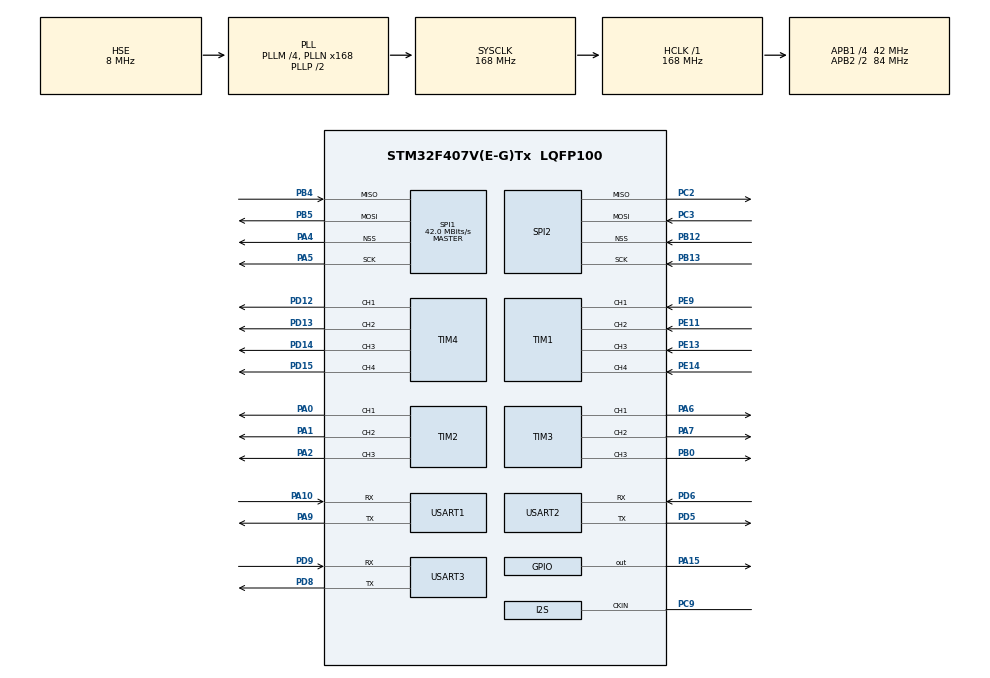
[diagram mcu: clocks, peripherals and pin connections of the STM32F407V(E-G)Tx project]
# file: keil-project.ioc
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Mcu.Family=STM32F4
Mcu.Name=STM32F407V(E-G)Tx
Mcu.Package=LQFP100
NVIC.PriorityGroup=NVIC_PRIORITYGROUP_4
PA0-WKUP.Signal=S_TIM2_CH1_ETR
PA1.Signal=S_TIM2_CH2
PA10.Mode=Asynchronous
PA10.Signal=USART1_RX
PA11.Signal=USART1_CTS
PA12.Signal=USART1_RTS
PA13.Mode=Trace-Asynchronous_SW
PA13.Signal=SYS_JTMS-SWDIO
PA14.Mode=Trace-Asynchronous_SW
PA14.Signal=SYS_JTCK-SWCLK
PA15.Signal=GPIO_Output
PA2.Signal=S_TIM2_CH3
PA4.Mode=NSS_Signal_Hard_Output
PA4.Signal=SPI1_NSS
PA5.Mode=Full_Duplex_Master
PA5.Signal=SPI1_SCK
PA6.Signal=S_TIM3_CH1
PA7.Signal=S_TIM3_CH2
PA8.Signal=USART1_CK
PA9.Mode=Asynchronous
PA9.Signal=USART1_TX
PB0.Signal=S_TIM3_CH3
PB12.Mode=NSS_Signal_Hard_Input
PB12.Signal=SPI2_NSS
PB13.Mode=Full_Duplex_Slave
PB13.Signal=SPI2_SCK
PB3.Mode=Trace-Asynchronous_SW
PB3.Signal=SYS_JTDO-SWO
PB4.Mode=Full_Duplex_Master
PB4.Signal=SPI1_MISO
PB5.Mode=Full_Duplex_Master
PB5.Signal=SPI1_MOSI
PC10.Signal=I2S3_CK
PC11.Signal=I2S3_ext_SD
PC12.Signal=I2S3_SD
PC2.Mode=Full_Duplex_Slave
PC2.Signal=SPI2_MISO
PC3.Mode=Full_Duplex_Slave
PC3.Signal=SPI2_MOSI
PC9.Mode=Audio_ClockIn
PC9.Signal=I2S_CKIN
PD12.Signal=S_TIM4_CH1
PD13.Signal=S_TIM4_CH2
PD14.Signal=S_TIM4_CH3
PD15.Signal=S_TIM4_CH4
PD5.Mode=Asynchronous
PD5.Signal=USART2_TX
PD6.Mode=Asynchronous
PD6.Signal=USART2_RX
PD8.Mode=Asynchronous
PD8.Signal=USART3_TX
PD9.Mode=Asynchronous
PD9.Signal=USART3_RX
PE11.Signal=S_TIM1_CH2
PE13.Signal=S_TIM1_CH3
PE14.Signal=S_TIM1_CH4
PE9.Signal=S_TIM1_CH1
PH0-OSC_IN.Mode=HSE-External-Clock-Source
PH0-OSC_IN.Signal=RCC_OSC_IN
PH1-OSC_OUT.Mode=HSE-External-Clock-Source
PH1-OSC_OUT.Signal=RCC_OSC_OUT
ProjectManager.HeapSize=0x200
ProjectManager.StackSize=0x400
ProjectManager.TargetToolchain=MDK-ARM V4
RCC.48MHZClocksFreq_Value=48000000
RCC.AHBFreq_Value=168000000
RCC.APB1CLKDivider=RCC_HCLK_DIV4
RCC.APB1Freq_Value=42000000
RCC.APB1TimFreq_Value=84000000
RCC.APB2CLKDivider=RCC_HCLK_DIV2
RCC.APB2Freq_Value=84000000
RCC.APB2TimFreq_Value=168000000
RCC.CortexFreq_Value=168000000
RCC.HCLKFreq_Value=168000000
RCC.HSE_VALUE=8000000
RCC.HSI_VALUE=16000000
RCC.I2SClockSource=I2S_CLOCK_EXTERNAL
RCC.LSE_VALUE=32768
RCC.PLLM=4
RCC.PLLN=168
RCC.PLLQ=7
RCC.PLLSourceVirtual=RCC_PLLSOURCE_HSE
RCC.SYSCLKFreq_VALUE=168000000
RCC.SYSCLKSource=RCC_SYSCLKSOURCE_PLLCLK
RCC.VCOOutputFreq_Value=336000000
SH.S_TIM1_CH1.0=TIM1_CH1,Input_Capture1_from_TI1
SH.S_TIM1_CH2.0=TIM1_CH2,Input_Capture2_from_TI2
SH.S_TIM1_CH3.0=TIM1_CH3,Input_Capture3_from_TI3
SH.S_TIM1_CH4.0=TIM1_CH4,Input_Capture4_from_TI4
SH.S_TIM2_CH1_ETR.0=TIM2_CH1,PWM Generation1 CH1
SH.S_TIM2_CH2.0=TIM2_CH2,PWM Generation2 CH2
SH.S_TIM2_CH3.0=TIM2_CH3,PWM Generation3 CH3
SH.S_TIM3_CH1.0=TIM3_CH1,PWM Generation1 CH1
SH.S_TIM3_CH2.0=TIM3_CH2,PWM Generation2 CH2
SH.S_TIM3_CH3.0=TIM3_CH3,PWM Generation3 CH3
SH.S_TIM4_CH1.0=TIM4_CH1,PWM Generation1 CH1
SH.S_TIM4_CH2.0=TIM4_CH2,PWM Generation2 CH2
SH.S_TIM4_CH3.0=TIM4_CH3,PWM Generation3 CH3
SH.S_TIM4_CH4.0=TIM4_CH4,PWM Generation4 CH4
SPI1.CalculateBaudRate=42.0 MBits/s
SPI1.Mode=SPI_MODE_MASTER
SPI1.VirtualNSS=VM_NSSHARD
SPI2.VirtualNSS=VM_NSSHARD
SPI2.VirtualType=VM_SLAVE
TIM1.Channel-Input_Capture2_from_TI2=TIM_CHANNEL_2
TIM1.Channel-Input_Capture3_from_TI3=TIM_CHANNEL_3
TIM1.Channel-Input_Capture4_from_TI4=TIM_CHANNEL_4
TIM2.Channel-PWM\ Generation2\ CH2=TIM_CHANNEL_2
TIM2.Channel-PWM\ Generation3\ CH3=TIM_CHANNEL_3
TIM3.Channel-PWM\ Generation2\ CH2=TIM_CHANNEL_2
TIM3.Channel-PWM\ Generation3\ CH3=TIM_CHANNEL_3
TIM4.Channel-PWM\ Generation2\ CH2=TIM_CHANNEL_2
TIM4.Channel-PWM\ Generation3\ CH3=TIM_CHANNEL_3
TIM4.Channel-PWM\ Generation4\ CH4=TIM_CHANNEL_4
VP_TIM1_VS_ClockSourceINT.Mode=Internal
VP_TIM2_VS_ClockSourceINT.Mode=Internal
VP_TIM3_VS_ClockSourceINT.Mode=Internal
VP_TIM4_VS_ClockSourceINT.Mode=Internal
board=keil-project

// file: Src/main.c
/**
  ******************************************************************************
  * File Name          : main.c
  * Description        : Main program body
  ******************************************************************************
  *
  * COPYRIGHT(c) 2016 STMicroelectronics
  *
  * Redistribution and use in source and binary forms, with or without modification,
  * are permitted provided that the following conditions are met:
  *   1. Redistributions of source code must retain the above copyright notice,
  *      this list of conditions and the following disclaimer.
  *   2. Redistributions in binary form must reproduce the above copyright notice,
  *      this list of conditions and the following disclaimer in the documentation
  *      and/or other materials provided with the distribution.
  *   3. Neither the name of STMicroelectronics nor the names of its contributors
  *      may be used to endorse or promote products derived from this software
  *      without specific prior written permission.
  *
  * THIS SOFTWARE IS PROVIDED BY THE COPYRIGHT HOLDERS AND CONTRIBUTORS "AS IS"
  * AND ANY EXPRESS OR IMPLIED WARRANTIES, INCLUDING, BUT NOT LIMITED TO, THE
  * IMPLIED WARRANTIES OF MERCHANTABILITY AND FITNESS FOR A PARTICULAR PURPOSE ARE
  * DISCLAIMED. IN NO EVENT SHALL THE COPYRIGHT HOLDER OR CONTRIBUTORS BE LIABLE
  * FOR ANY DIRECT, INDIRECT, INCIDENTAL, SPECIAL, EXEMPLARY, OR CONSEQUENTIAL
  * DAMAGES (INCLUDING, BUT NOT LIMITED TO, PROCUREMENT OF SUBSTITUTE GOODS OR
  * SERVICES; LOSS OF USE, DATA, OR PROFITS; OR BUSINESS INTERRUPTION) HOWEVER
  * CAUSED AND ON ANY THEORY OF LIABILITY, WHETHER IN CONTRACT, STRICT LIABILITY,
  * OR TORT (INCLUDING NEGLIGENCE OR OTHERWISE) ARISING IN ANY WAY OUT OF THE USE
  * OF THIS SOFTWARE, EVEN IF ADVISED OF THE POSSIBILITY OF SUCH DAMAGE.
  *
  ******************************************************************************
  */
#include "stm32f4xx_hal.h"

SPI_HandleTypeDef hspi1;
SPI_HandleTypeDef hspi2;

TIM_HandleTypeDef htim1;
TIM_HandleTypeDef htim2;
TIM_HandleTypeDef htim3;
TIM_HandleTypeDef htim4;

UART_HandleTypeDef huart1;
UART_HandleTypeDef huart2;
UART_HandleTypeDef huart3;

/* USER CODE BEGIN PV */
/* Private variables ---------------------------------------------------------*/

/* USER CODE END PV */

void SystemClock_Config(void);
static void MX_GPIO_Init(void);
static void MX_SPI1_Init(void);
static void MX_SPI2_Init(void);
static void MX_TIM1_Init(void);
static void MX_TIM2_Init(void);
static void MX_TIM3_Init(void);
static void MX_TIM4_Init(void);
static void MX_USART1_UART_Init(void);
static void MX_USART2_UART_Init(void);
static void MX_USART3_UART_Init(void);

void HAL_TIM_MspPostInit(TIM_HandleTypeDef *htim);

/* USER CODE BEGIN PFP */
/* Private function prototypes -----------------------------------------------*/

/* USER CODE END PFP */

int main(void)
{

  /* MCU Configuration----------------------------------------------------------*/

  /* Reset of all peripherals, Initializes the Flash interface and the Systick. */
  HAL_Init();

  /* Configure the system clock */
  SystemClock_Config();

  /* Initialize all configured peripherals */
  MX_GPIO_Init();
  MX_SPI1_Init();
  MX_SPI2_Init();
  MX_TIM1_Init();
  MX_TIM2_Init();
  MX_TIM3_Init();
  MX_TIM4_Init();
  MX_USART1_UART_Init();
  MX_USART2_UART_Init();
  MX_USART3_UART_Init();

  /* Infinite loop */
  /* USER CODE BEGIN WHILE */

 uint8_t data[] = { 0x05, 0x06, 0x07};
  while (1)
  {

          HAL_Delay(200);
          HAL_UART_Transmit(&huart1, data, 3, 1000);
  /* USER CODE END WHILE */

  }

}

/** System Clock Configuration
*/
void SystemClock_Config(void)
{

  RCC_OscInitTypeDef RCC_OscInitStruct;
  RCC_ClkInitTypeDef RCC_ClkInitStruct;

  __HAL_RCC_PWR_CLK_ENABLE();

  __HAL_PWR_VOLTAGESCALING_CONFIG(PWR_REGULATOR_VOLTAGE_SCALE1);

  RCC_OscInitStruct.OscillatorType = RCC_OSCILLATORTYPE_HSE;
  RCC_OscInitStruct.HSEState = RCC_HSE_BYPASS;
  RCC_OscInitStruct.PLL.PLLState = RCC_PLL_ON;
  RCC_OscInitStruct.PLL.PLLSource = RCC_PLLSOURCE_HSE;
  RCC_OscInitStruct.PLL.PLLM = 4;
  RCC_OscInitStruct.PLL.PLLN = 168;
  RCC_OscInitStruct.PLL.PLLP = RCC_PLLP_DIV2;
  RCC_OscInitStruct.PLL.PLLQ = 7;
  HAL_RCC_OscConfig(&RCC_OscInitStruct);

  RCC_ClkInitStruct.ClockType = RCC_CLOCKTYPE_HCLK|RCC_CLOCKTYPE_SYSCLK
                              |RCC_CLOCKTYPE_PCLK1|RCC_CLOCKTYPE_PCLK2;
  RCC_ClkInitStruct.SYSCLKSource = RCC_SYSCLKSOURCE_PLLCLK;
  RCC_ClkInitStruct.AHBCLKDivider = RCC_SYSCLK_DIV1;
  RCC_ClkInitStruct.APB1CLKDivider = RCC_HCLK_DIV4;
  RCC_ClkInitStruct.APB2CLKDivider = RCC_HCLK_DIV2;
  HAL_RCC_ClockConfig(&RCC_ClkInitStruct, FLASH_LATENCY_5);

  HAL_SYSTICK_Config(HAL_RCC_GetHCLKFreq()/1000);

  HAL_SYSTICK_CLKSourceConfig(SYSTICK_CLKSOURCE_HCLK);

  /* SysTick_IRQn interrupt configuration */
  HAL_NVIC_SetPriority(SysTick_IRQn, 0, 0);
}

/* SPI1 init function */
void MX_SPI1_Init(void)
{

  hspi1.Instance = SPI1;
  hspi1.Init.Mode = SPI_MODE_MASTER;
  hspi1.Init.Direction = SPI_DIRECTION_2LINES;
  hspi1.Init.DataSize = SPI_DATASIZE_8BIT;
  hspi1.Init.CLKPolarity = SPI_POLARITY_LOW;
  hspi1.Init.CLKPhase = SPI_PHASE_1EDGE;
  hspi1.Init.NSS = SPI_NSS_HARD_OUTPUT;
  hspi1.Init.BaudRatePrescaler = SPI_BAUDRATEPRESCALER_2;
  hspi1.Init.FirstBit = SPI_FIRSTBIT_MSB;
  hspi1.Init.TIMode = SPI_TIMODE_DISABLE;
  hspi1.Init.CRCCalculation = SPI_CRCCALCULATION_DISABLE;
  hspi1.Init.CRCPolynomial = 10;
  HAL_SPI_Init(&hspi1);

}

/* SPI2 init function */
void MX_SPI2_Init(void)
{

  hspi2.Instance = SPI2;
  hspi2.Init.Mode = SPI_MODE_SLAVE;
  hspi2.Init.Direction = SPI_DIRECTION_2LINES;
  hspi2.Init.DataSize = SPI_DATASIZE_8BIT;
  hspi2.Init.CLKPolarity = SPI_POLARITY_LOW;
  hspi2.Init.CLKPhase = SPI_PHASE_1EDGE;
  hspi2.Init.NSS = SPI_NSS_HARD_INPUT;
  hspi2.Init.FirstBit = SPI_FIRSTBIT_MSB;
  hspi2.Init.TIMode = SPI_TIMODE_DISABLE;
  hspi2.Init.CRCCalculation = SPI_CRCCALCULATION_DISABLE;
  hspi2.Init.CRCPolynomial = 10;
  HAL_SPI_Init(&hspi2);

}

/* TIM1 init function */
void MX_TIM1_Init(void)
{

  TIM_ClockConfigTypeDef sClockSourceConfig;
  TIM_MasterConfigTypeDef sMasterConfig;
  TIM_IC_InitTypeDef sConfigIC;

  htim1.Instance = TIM1;
  htim1.Init.Prescaler = 0;
  htim1.Init.CounterMode = TIM_COUNTERMODE_UP;
  htim1.Init.Period = 0;
  htim1.Init.ClockDivision = TIM_CLOCKDIVISION_DIV1;
  htim1.Init.RepetitionCounter = 0;
  HAL_TIM_Base_Init(&htim1);

  sClockSourceConfig.ClockSource = TIM_CLOCKSOURCE_INTERNAL;
  HAL_TIM_ConfigClockSource(&htim1, &sClockSourceConfig);

  HAL_TIM_IC_Init(&htim1);

  sMasterConfig.MasterOutputTrigger = TIM_TRGO_RESET;
  sMasterConfig.MasterSlaveMode = TIM_MASTERSLAVEMODE_DISABLE;
  HAL_TIMEx_MasterConfigSynchronization(&htim1, &sMasterConfig);

  sConfigIC.ICPolarity = TIM_INPUTCHANNELPOLARITY_RISING;
  sConfigIC.ICSelection = TIM_ICSELECTION_DIRECTTI;
  sConfigIC.ICPrescaler = TIM_ICPSC_DIV1;
  sConfigIC.ICFilter = 0;
  HAL_TIM_IC_ConfigChannel(&htim1, &sConfigIC, TIM_CHANNEL_1);

  HAL_TIM_IC_ConfigChannel(&htim1, &sConfigIC, TIM_CHANNEL_2);

  HAL_TIM_IC_ConfigChannel(&htim1, &sConfigIC, TIM_CHANNEL_3);

  HAL_TIM_IC_ConfigChannel(&htim1, &sConfigIC, TIM_CHANNEL_4);

}

/* TIM2 init function */
void MX_TIM2_Init(void)
{

  TIM_ClockConfigTypeDef sClockSourceConfig;
  TIM_MasterConfigTypeDef sMasterConfig;
  TIM_OC_InitTypeDef sConfigOC;

  htim2.Instance = TIM2;
  htim2.Init.Prescaler = 0;
  htim2.Init.CounterMode = TIM_COUNTERMODE_UP;
  htim2.Init.Period = 0;
  htim2.Init.ClockDivision = TIM_CLOCKDIVISION_DIV1;
  HAL_TIM_Base_Init(&htim2);

  sClockSourceConfig.ClockSource = TIM_CLOCKSOURCE_INTERNAL;
  HAL_TIM_ConfigClockSource(&htim2, &sClockSourceConfig);

  HAL_TIM_PWM_Init(&htim2);

  sMasterConfig.MasterOutputTrigger = TIM_TRGO_RESET;
  sMasterConfig.MasterSlaveMode = TIM_MASTERSLAVEMODE_DISABLE;
  HAL_TIMEx_MasterConfigSynchronization(&htim2, &sMasterConfig);

  sConfigOC.OCMode = TIM_OCMODE_PWM1;
  sConfigOC.Pulse = 0;
  sConfigOC.OCPolarity = TIM_OCPOLARITY_HIGH;
  sConfigOC.OCFastMode = TIM_OCFAST_DISABLE;
  HAL_TIM_PWM_ConfigChannel(&htim2, &sConfigOC, TIM_CHANNEL_1);

  HAL_TIM_PWM_ConfigChannel(&htim2, &sConfigOC, TIM_CHANNEL_2);

  HAL_TIM_PWM_ConfigChannel(&htim2, &sConfigOC, TIM_CHANNEL_3);

  HAL_TIM_MspPostInit(&htim2);

}

/* TIM3 init function */
void MX_TIM3_Init(void)
{

  TIM_ClockConfigTypeDef sClockSourceConfig;
  TIM_MasterConfigTypeDef sMasterConfig;
  TIM_OC_InitTypeDef sConfigOC;

  htim3.Instance = TIM3;
  htim3.Init.Prescaler = 0;
  htim3.Init.CounterMode = TIM_COUNTERMODE_UP;
  htim3.Init.Period = 0;
  htim3.Init.ClockDivision = TIM_CLOCKDIVISION_DIV1;
  HAL_TIM_Base_Init(&htim3);

  sClockSourceConfig.ClockSource = TIM_CLOCKSOURCE_INTERNAL;
  HAL_TIM_ConfigClockSource(&htim3, &sClockSourceConfig);

  HAL_TIM_PWM_Init(&htim3);

  sMasterConfig.MasterOutputTrigger = TIM_TRGO_RESET;
  sMasterConfig.MasterSlaveMode = TIM_MASTERSLAVEMODE_DISABLE;
  HAL_TIMEx_MasterConfigSynchronization(&htim3, &sMasterConfig);

  sConfigOC.OCMode = TIM_OCMODE_PWM1;
  sConfigOC.Pulse = 0;
  sConfigOC.OCPolarity = TIM_OCPOLARITY_HIGH;
  sConfigOC.OCFastMode = TIM_OCFAST_DISABLE;
  HAL_TIM_PWM_ConfigChannel(&htim3, &sConfigOC, TIM_CHANNEL_1);

  HAL_TIM_PWM_ConfigChannel(&htim3, &sConfigOC, TIM_CHANNEL_2);

  HAL_TIM_PWM_ConfigChannel(&htim3, &sConfigOC, TIM_CHANNEL_3);

  HAL_TIM_MspPostInit(&htim3);

}

/* TIM4 init function */
void MX_TIM4_Init(void)
{

  TIM_ClockConfigTypeDef sClockSourceConfig;
  TIM_MasterConfigTypeDef sMasterConfig;
  TIM_OC_InitTypeDef sConfigOC;

  htim4.Instance = TIM4;
  htim4.Init.Prescaler = 0;
  htim4.Init.CounterMode = TIM_COUNTERMODE_UP;
  htim4.Init.Period = 0;
  htim4.Init.ClockDivision = TIM_CLOCKDIVISION_DIV1;
  HAL_TIM_Base_Init(&htim4);

  sClockSourceConfig.ClockSource = TIM_CLOCKSOURCE_INTERNAL;
  HAL_TIM_ConfigClockSource(&htim4, &sClockSourceConfig);

  HAL_TIM_PWM_Init(&htim4);

  sMasterConfig.MasterOutputTrigger = TIM_TRGO_RESET;
  sMasterConfig.MasterSlaveMode = TIM_MASTERSLAVEMODE_DISABLE;
  HAL_TIMEx_MasterConfigSynchronization(&htim4, &sMasterConfig);

  sConfigOC.OCMode = TIM_OCMODE_PWM1;
  sConfigOC.Pulse = 0;
  sConfigOC.OCPolarity = TIM_OCPOLARITY_HIGH;
  sConfigOC.OCFastMode = TIM_OCFAST_DISABLE;
  HAL_TIM_PWM_ConfigChannel(&htim4, &sConfigOC, TIM_CHANNEL_1);

  HAL_TIM_PWM_ConfigChannel(&htim4, &sConfigOC, TIM_CHANNEL_2);

  HAL_TIM_PWM_ConfigChannel(&htim4, &sConfigOC, TIM_CHANNEL_3);

  HAL_TIM_PWM_ConfigChannel(&htim4, &sConfigOC, TIM_CHANNEL_4);

  HAL_TIM_MspPostInit(&htim4);

}

/* USART1 init function */
void MX_USART1_UART_Init(void)
{

  huart1.Instance = USART1;
  huart1.Init.BaudRate = 115200;
  huart1.Init.WordLength = UART_WORDLENGTH_8B;
  huart1.Init.StopBits = UART_STOPBITS_1;
  huart1.Init.Parity = UART_PARITY_NONE;
  huart1.Init.Mode = UART_MODE_TX_RX;
  huart1.Init.HwFlowCtl = UART_HWCONTROL_NONE;
  huart1.Init.OverSampling = UART_OVERSAMPLING_16;
  HAL_UART_Init(&huart1);

}

/* USART2 init function */
void MX_USART2_UART_Init(void)
{

  huart2.Instance = USART2;
  huart2.Init.BaudRate = 115200;
  huart2.Init.WordLength = UART_WORDLENGTH_8B;
  huart2.Init.StopBits = UART_STOPBITS_1;
  huart2.Init.Parity = UART_PARITY_NONE;
  huart2.Init.Mode = UART_MODE_TX_RX;
  huart2.Init.HwFlowCtl = UART_HWCONTROL_NONE;
  huart2.Init.OverSampling = UART_OVERSAMPLING_16;
  HAL_UART_Init(&huart2);

}

/* USART3 init function */
void MX_USART3_UART_Init(void)
{

  huart3.Instance = USART3;
  huart3.Init.BaudRate = 115200;
  huart3.Init.WordLength = UART_WORDLENGTH_8B;
  huart3.Init.StopBits = UART_STOPBITS_1;
  huart3.Init.Parity = UART_PARITY_NONE;
  huart3.Init.Mode = UART_MODE_TX_RX;
  huart3.Init.HwFlowCtl = UART_HWCONTROL_NONE;
  huart3.Init.OverSampling = UART_OVERSAMPLING_16;
  HAL_UART_Init(&huart3);

}

/** Configure pins as
        * Analog
        * Input
        * Output
        * EVENT_OUT
        * EXTI
     PC9   ------> I2S_CKIN
     PC10   ------> I2S3_CK
     PC11   ------> I2S3_ext_SD
     PC12   ------> I2S3_SD
*/
void MX_GPIO_Init(void)
{

  GPIO_InitTypeDef GPIO_InitStruct;

  /* GPIO Ports Clock Enable */
  __HAL_RCC_GPIOH_CLK_ENABLE();
  __HAL_RCC_GPIOC_CLK_ENABLE();
  __HAL_RCC_GPIOA_CLK_ENABLE();
  __HAL_RCC_GPIOB_CLK_ENABLE();
  __HAL_RCC_GPIOE_CLK_ENABLE();
  __HAL_RCC_GPIOD_CLK_ENABLE();

  /*Configure GPIO pin : PC9 */
  GPIO_InitStruct.Pin = GPIO_PIN_9;
  GPIO_InitStruct.Mode = GPIO_MODE_AF_PP;
  GPIO_InitStruct.Pull = GPIO_NOPULL;
  GPIO_InitStruct.Speed = GPIO_SPEED_FREQ_LOW;
  GPIO_InitStruct.Alternate = GPIO_AF5_SPI1;
  HAL_GPIO_Init(GPIOC, &GPIO_InitStruct);

  /*Configure GPIO pin : PA15 */
  GPIO_InitStruct.Pin = GPIO_PIN_15;
  GPIO_InitStruct.Mode = GPIO_MODE_OUTPUT_PP;
  GPIO_InitStruct.Pull = GPIO_NOPULL;
  GPIO_InitStruct.Speed = GPIO_SPEED_FREQ_LOW;
  HAL_GPIO_Init(GPIOA, &GPIO_InitStruct);

  /*Configure GPIO pins : PC10 PC12 */
  GPIO_InitStruct.Pin = GPIO_PIN_10|GPIO_PIN_12;
  GPIO_InitStruct.Mode = GPIO_MODE_AF_PP;
  GPIO_InitStruct.Pull = GPIO_NOPULL;
  GPIO_InitStruct.Speed = GPIO_SPEED_FREQ_LOW;
  GPIO_InitStruct.Alternate = GPIO_AF6_SPI3;
  HAL_GPIO_Init(GPIOC, &GPIO_InitStruct);

  /*Configure GPIO pin : PC11 */
  GPIO_InitStruct.Pin = GPIO_PIN_11;
  GPIO_InitStruct.Mode = GPIO_MODE_AF_PP;
  GPIO_InitStruct.Pull = GPIO_NOPULL;
  GPIO_InitStruct.Speed = GPIO_SPEED_FREQ_LOW;
  GPIO_InitStruct.Alternate = GPIO_AF5_I2S3ext;
  HAL_GPIO_Init(GPIOC, &GPIO_InitStruct);

  /*Configure GPIO pin Output Level */
  HAL_GPIO_WritePin(GPIOA, GPIO_PIN_15, GPIO_PIN_RESET);

}

/************************ (C) COPYRIGHT STMicroelectronics *****END OF FILE****/
